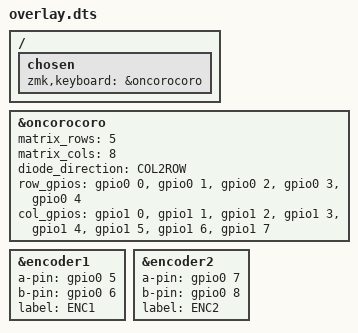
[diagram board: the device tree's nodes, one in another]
/ {
  chosen {
    zmk,keyboard = &oncorocoro;
  };
};

&oncorocoro {
  matrix_rows = <5>;
  matrix_cols = <8>;
  diode_direction = <COL2ROW>;

  row_gpios = <&gpio0 0>, <&gpio0 1>, <&gpio0 2>, <&gpio0 3>, <&gpio0 4>;
  col_gpios = <&gpio1 0>, <&gpio1 1>, <&gpio1 2>, <&gpio1 3>, <&gpio1 4>, <&gpio1 5>, <&gpio1 6>, <&gpio1 7>;
};

&encoder1 {
  a-pin = <&gpio0 5>;
  b-pin = <&gpio0 6>;
  label = "ENC1";
};

&encoder2 {
  a-pin = <&gpio0 7>;
  b-pin = <&gpio0 8>;
  label = "ENC2";
};


